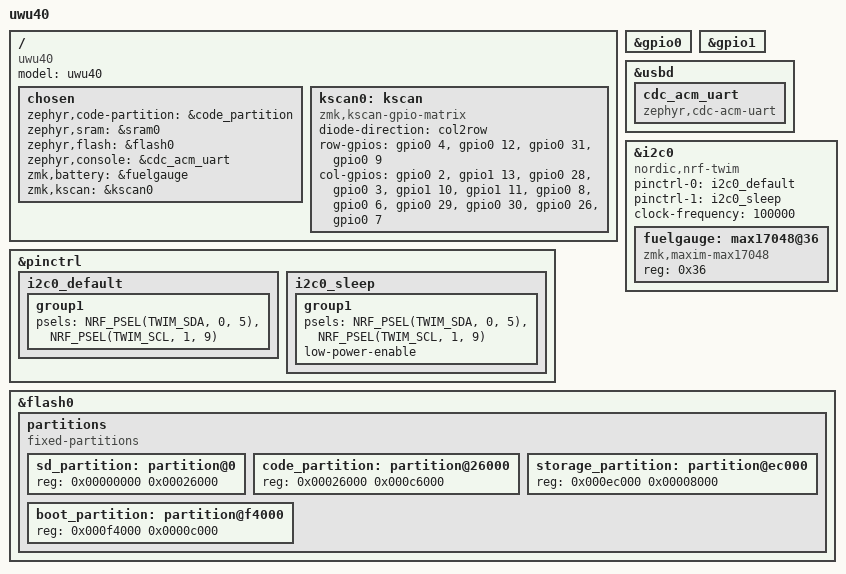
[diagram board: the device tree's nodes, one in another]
/*
 * Copyright (c) 2023 The ZMK Contributors
 *
 * SPDX-License-Identifier: MIT
 */

/dts-v1/;
#include <nordic/nrf52840_qiaa.dtsi>
#include <dt-bindings/zmk/matrix_transform.h>

#include "uwu40-transforms.dtsi"
#include "uwu40-layouts.dtsi"


/ {
    model = "uwu40";
    compatible = "uwu40";

    chosen {
        zephyr,code-partition = &code_partition;
        zephyr,sram = &sram0;
        zephyr,flash = &flash0;
        zephyr,console = &cdc_acm_uart;
        zmk,battery = &fuelgauge;
        zmk,kscan = &kscan0;
    };

kscan0: kscan {
  compatible = "zmk,kscan-gpio-matrix";
  diode-direction = "col2row";
  row-gpios
      = <&gpio0 4 (GPIO_ACTIVE_HIGH | GPIO_PULL_DOWN)>
      , <&gpio0 12 (GPIO_ACTIVE_HIGH | GPIO_PULL_DOWN)>
      , <&gpio0 31 (GPIO_ACTIVE_HIGH | GPIO_PULL_DOWN)>
      , <&gpio0 9 (GPIO_ACTIVE_HIGH | GPIO_PULL_DOWN)>
      ;
  col-gpios
      = <&gpio0 2 GPIO_ACTIVE_HIGH>
      , <&gpio1 13 GPIO_ACTIVE_HIGH>
      , <&gpio0 28 GPIO_ACTIVE_HIGH>
      , <&gpio0 3 GPIO_ACTIVE_HIGH>
      , <&gpio1 10 GPIO_ACTIVE_HIGH>
      , <&gpio1 11 GPIO_ACTIVE_HIGH>
      , <&gpio0 8 GPIO_ACTIVE_HIGH>
      , <&gpio0 6 GPIO_ACTIVE_HIGH>
      , <&gpio0 29 GPIO_ACTIVE_HIGH>
      , <&gpio0 30 GPIO_ACTIVE_HIGH>
      , <&gpio0 26 GPIO_ACTIVE_HIGH>
      , <&gpio0 7 GPIO_ACTIVE_HIGH>
      ;
  };
};

&gpio0 {
    status = "okay";
};

&gpio1 {
    status = "okay";
};

&usbd {
    status = "okay";
    cdc_acm_uart: cdc_acm_uart {
        compatible = "zephyr,cdc-acm-uart";
    };
};

&pinctrl {
  i2c0_default: i2c0_default {
    group1 {
    psels = <NRF_PSEL(TWIM_SDA, 0, 5)>,
            <NRF_PSEL(TWIM_SCL, 1, 9)>;
    };
  };
  i2c0_sleep: i2c0_sleep {
    group1 {
    psels = <NRF_PSEL(TWIM_SDA, 0, 5)>,
            <NRF_PSEL(TWIM_SCL, 1, 9)>;
    low-power-enable;
    };
  };
};

&i2c0 {
    status = "okay";
    compatible = "nordic,nrf-twim";
    pinctrl-0 = <&i2c0_default>;
    pinctrl-1 = <&i2c0_sleep>;
    pinctrl-names = "default", "sleep";
    clock-frequency = <100000>;

    fuelgauge: max17048@36 {
        compatible = "zmk,maxim-max17048";
        reg = <0x36>;
    };
};

zephyr_udc0: &usbd {
  status = "okay";
  cdc_acm_uart: cdc_acm_uart {
  compatible = "zephyr,cdc-acm-uart";
  };
};

&flash0 {
    partitions {
        compatible = "fixed-partitions";
        #address-cells = <1>;
        #size-cells = <1>;

        sd_partition: partition@0 {
            reg = <0x00000000 0x00026000>;
        };
        code_partition: partition@26000 {
            reg = <0x00026000 0x000c6000>;
        };

        /*
         * The flash starting at 0x000ec000 and ending at
         * 0x000f3fff is reserved for use by the application.
         */

        /*
         * Storage partition will be used by FCB/LittleFS/NVS
         * if enabled.
         */
        storage_partition: partition@ec000 {
            reg = <0x000ec000 0x00008000>;
        };

        boot_partition: partition@f4000 {
            reg = <0x000f4000 0x0000c000>;
        };
    };
};
